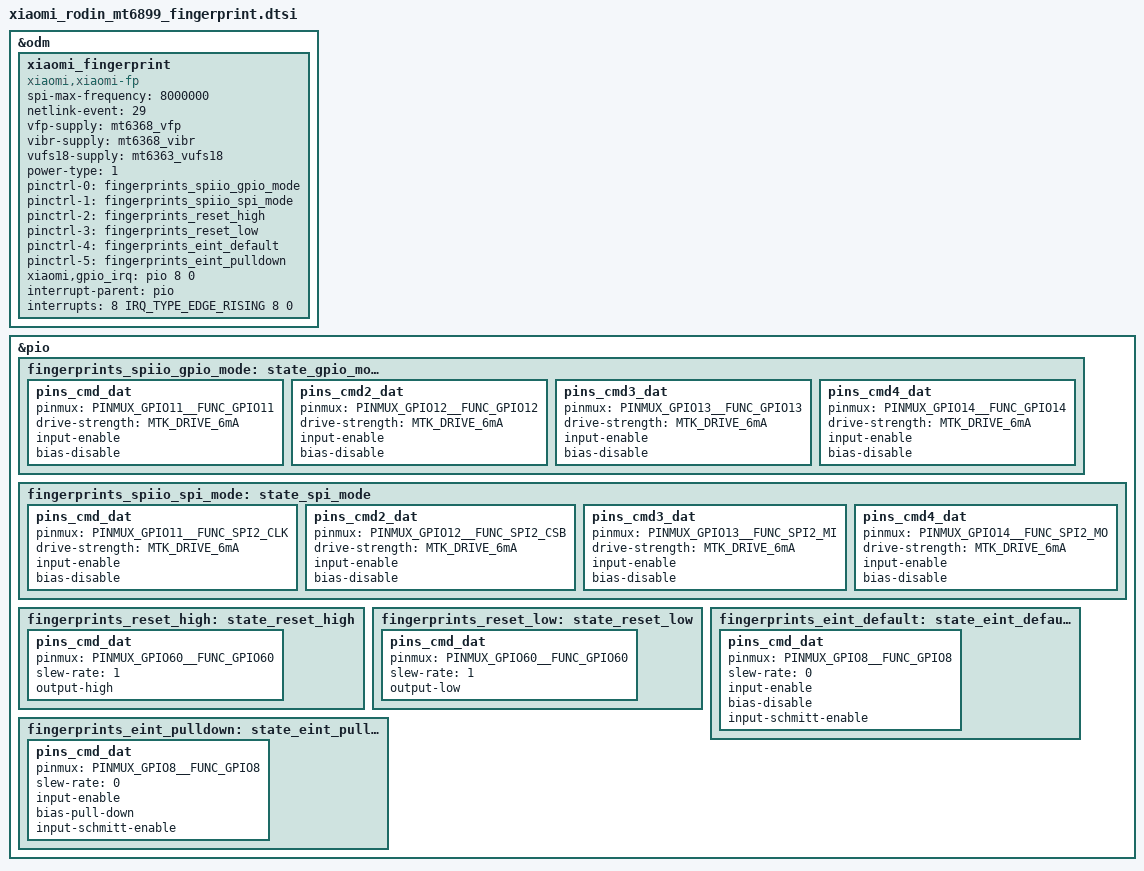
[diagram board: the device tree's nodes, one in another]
// SPDX-License-Identifier: (GPL-2.0 OR MIT)
/*
 * Copyright (C) 2024 MediaTek Inc.
 */

/* fingerprint start */

&odm {
	xiaomi_fingerprint: xiaomi_fingerprint {
		compatible = "xiaomi,xiaomi-fp";
		spi-max-frequency = <8000000>;
		netlink-event = <29>;
		vfp-supply = <&mt6368_vfp>;
		vibr-supply = <&mt6368_vibr>;
		vufs18-supply = <&mt6363_vufs18>;
		power-type = <1>;
		pinctrl-names = "spiio_gpio_mode", "spiio_spi_mode", "reset_high", "reset_low", "eint_default", "eint_pulldown";
		pinctrl-0 = <&fingerprints_spiio_gpio_mode>;
		pinctrl-1 = <&fingerprints_spiio_spi_mode>;
		pinctrl-2 = <&fingerprints_reset_high>;
		pinctrl-3 = <&fingerprints_reset_low>;
		pinctrl-4 = <&fingerprints_eint_default>;
		pinctrl-5 = <&fingerprints_eint_pulldown>;
		xiaomi,gpio_irq = <&pio 8 0>;
		interrupt-parent = <&pio>;
		interrupts = <8 IRQ_TYPE_EDGE_RISING 8 0>;
		status = "okay";
	};
};

&pio {
	fingerprints_spiio_gpio_mode: state_gpio_mode {
		pins_cmd_dat {
			pinmux = <PINMUX_GPIO11__FUNC_GPIO11>;
			drive-strength = <MTK_DRIVE_6mA>;
			input-enable;
			bias-disable;
		};
		pins_cmd2_dat {
			pinmux = <PINMUX_GPIO12__FUNC_GPIO12>;
			drive-strength = <MTK_DRIVE_6mA>;
			input-enable;
			bias-disable;
		};
		pins_cmd3_dat {
			pinmux = <PINMUX_GPIO13__FUNC_GPIO13>;
			drive-strength = <MTK_DRIVE_6mA>;
			input-enable;
			bias-disable;
		};
		pins_cmd4_dat {
			pinmux = <PINMUX_GPIO14__FUNC_GPIO14>;
			drive-strength = <MTK_DRIVE_6mA>;
			input-enable;
			bias-disable;
		};
	};
	fingerprints_spiio_spi_mode: state_spi_mode {
		pins_cmd_dat {
			pinmux = <PINMUX_GPIO11__FUNC_SPI2_CLK>;
			drive-strength = <MTK_DRIVE_6mA>;
			input-enable;
			bias-disable;
		};
		pins_cmd2_dat {
			pinmux = <PINMUX_GPIO12__FUNC_SPI2_CSB>;
			drive-strength = <MTK_DRIVE_6mA>;
			input-enable;
			bias-disable;
		};
		pins_cmd3_dat {
			pinmux = <PINMUX_GPIO13__FUNC_SPI2_MI>;
			drive-strength = <MTK_DRIVE_6mA>;
			input-enable;
			bias-disable;
		};
		pins_cmd4_dat {
			pinmux = <PINMUX_GPIO14__FUNC_SPI2_MO>;
			drive-strength = <MTK_DRIVE_6mA>;
			input-enable;
			bias-disable;
		};
	};

	fingerprints_reset_high: state_reset_high {
		pins_cmd_dat {
			pinmux = <PINMUX_GPIO60__FUNC_GPIO60>;
			slew-rate = <1>;
			output-high;
		};
	};
	fingerprints_reset_low: state_reset_low {
		pins_cmd_dat {
			pinmux = <PINMUX_GPIO60__FUNC_GPIO60>;
			slew-rate = <1>;
			output-low;
		};
	};
	fingerprints_eint_default: state_eint_default {
		pins_cmd_dat {
			pinmux = <PINMUX_GPIO8__FUNC_GPIO8>;
			slew-rate = <0>;
			input-enable;
			bias-disable;
			input-schmitt-enable;
		};
	};
	fingerprints_eint_pulldown: state_eint_pulldown {
		pins_cmd_dat {
			pinmux = <PINMUX_GPIO8__FUNC_GPIO8>;
			slew-rate = <0>;
			input-enable;
			bias-pull-down;
			input-schmitt-enable;
		};
	};
};

/* fingerprint end */
